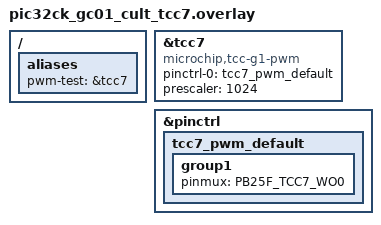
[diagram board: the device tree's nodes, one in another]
/*
 * Copyright (c) 2026 Microchip Technology Inc.
 *
 * SPDX-License-Identifier: Apache-2.0
 */

/ {
	aliases {
		pwm-test = &tcc7;
	};
};

&tcc7 {
	compatible = "microchip,tcc-g1-pwm";
	#pwm-cells = <3>;
	pinctrl-0 = <&tcc7_pwm_default>;
	pinctrl-names = "default";
	prescaler = <1024>;
	status = "okay";
};

&pinctrl {
	tcc7_pwm_default: tcc7_pwm_default {
		group1 {
			pinmux = <PB25F_TCC7_WO0>;
		};
	};
};
